# BCM2711_GPIO register map
File version: 1
BCM2711 GPIO controller: pin functions, pulls, levels and event detection
Registers are read-write, no defined reset value unless marked. A register's access mark holds for its fields unless they carry their own. Offsets are from the block's base; lines under a group give offsets from that group; [hi:lo] are bit positions; {n}, {i} and the like mark numbered series; 'fields as' and 'values as' point back to an identical list; <NAME> marks a mode.

## Memory map
0x00000000 BCM2711_GPIO size 0xF4

## BCM2711_GPIO
Base 0x00000000
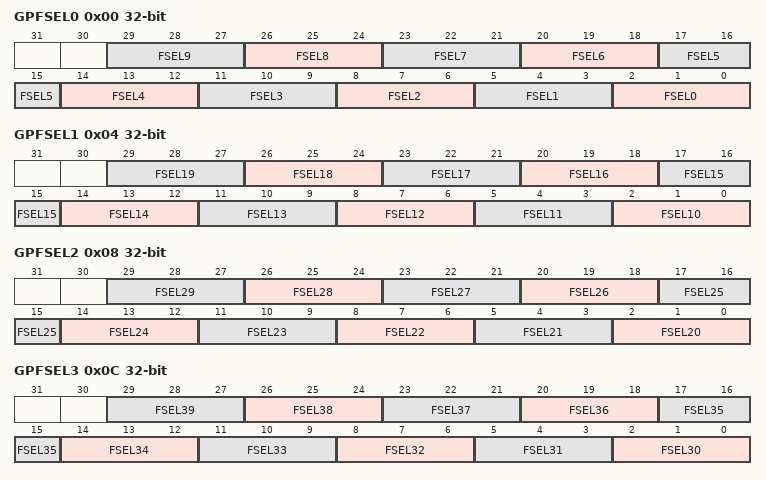
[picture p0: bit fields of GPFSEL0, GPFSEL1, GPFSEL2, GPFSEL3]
0x00 GPFSEL0 — Function select 0 (Table 64): GPIO 0 to 9, each an input, an output or one of its six alternate functions
  [3n+2:3n] FSEL{n} (n=0..9) — FSELn is GPIO n's function
    0=INPUT; 1=OUTPUT; {v}=ALT{v-4} (v=4..7); 3=ALT4; 2=ALT5
0x04 GPFSEL1 — Function select 1 (Table 65): GPIO 10 to 19, each an input, an output or one of its six alternate functions
  [3n-28:3n-30] FSEL{n} (n=10..19) — FSELn is GPIO n's function
    0=INPUT; 1=OUTPUT; {v}=ALT{v-4} (v=4..7); 3=ALT4; 2=ALT5
0x08 GPFSEL2 — Function select 2 (Table 66): GPIO 20 to 29, each an input, an output or one of its six alternate functions
  [3n-58:3n-60] FSEL{n} (n=20..29) — FSELn is GPIO n's function
    0=INPUT; 1=OUTPUT; {v}=ALT{v-4} (v=4..7); 3=ALT4; 2=ALT5
0x0C GPFSEL3 — Function select 3 (Table 67): GPIO 30 to 39, each an input, an output or one of its six alternate functions
  [3n-88:3n-90] FSEL{n} (n=30..39) — FSELn is GPIO n's function
    0=INPUT; 1=OUTPUT; {v}=ALT{v-4} (v=4..7); 3=ALT4; 2=ALT5
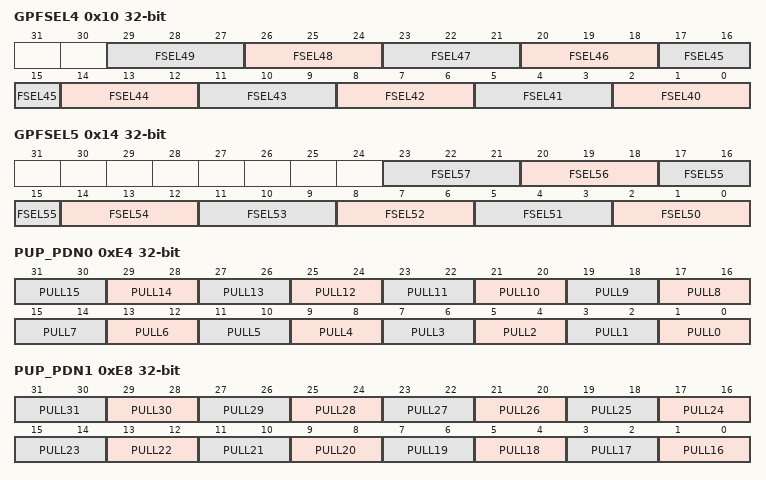
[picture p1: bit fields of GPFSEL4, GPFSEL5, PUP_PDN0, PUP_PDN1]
0x10 GPFSEL4 — Function select 4 (Table 68): GPIO 40 to 49, each an input, an output or one of its six alternate functions
  [3n-118:3n-120] FSEL{n} (n=40..49) — FSELn is GPIO n's function
    0=INPUT; 1=OUTPUT; {v}=ALT{v-4} (v=4..7); 3=ALT4; 2=ALT5
0x14 GPFSEL5 — Function select 5 (Table 69): GPIO 50 to 57, each an input, an output or one of its six alternate functions
  [3n-148:3n-150] FSEL{n} (n=50..57) — FSELn is GPIO n's function
    0=INPUT; 1=OUTPUT; {v}=ALT{v-4} (v=4..7); 3=ALT4; 2=ALT5
0x1C GPSET0 wo — Output set: 1 sets the pin's output, 0 has no effect (Table 70), one bit per GPIO 0 to 31
  [31:0] SET — Bit n is GPIO 0 + n
0x20 GPSET1 wo — Output set: 1 sets the pin's output, 0 has no effect (Table 71), one bit per GPIO 32 to 57
  [25:0] SET — Bit n is GPIO 32 + n
0x28 GPCLR0 wo — Output clear: 1 clears the pin's output, 0 has no effect (Table 72), one bit per GPIO 0 to 31
  [31:0] CLR — Bit n is GPIO 0 + n
0x2C GPCLR1 wo — Output clear: 1 clears the pin's output, 0 has no effect (Table 73), one bit per GPIO 32 to 57
  [25:0] CLR — Bit n is GPIO 32 + n
0x34 GPLEV0 ro — Pin level: 1 the pin is high (Table 74), one bit per GPIO 0 to 31
  [31:0] LEV — Bit n is GPIO 0 + n
0x38 GPLEV1 ro — Pin level: 1 the pin is high (Table 75), one bit per GPIO 32 to 57
  [25:0] LEV — Bit n is GPIO 32 + n
0x40 GPEDS0 — Event detect status: 1 once an enabled edge or level is seen on the pin; writing 1 clears it, and a level still present sets it again (Table 76), one bit per GPIO 0 to 31
  [31:0] EDS write-1-clears — Bit n is GPIO 0 + n
0x44 GPEDS1 — Event detect status: 1 once an enabled edge or level is seen on the pin; writing 1 clears it, and a level still present sets it again (Table 77), one bit per GPIO 32 to 57
  [25:0] EDS write-1-clears — Bit n is GPIO 32 + n
0x4C GPREN0 — Rising edge detect enable, sampled by the system clock (Table 78), one bit per GPIO 0 to 31
  [31:0] REN — Bit n is GPIO 0 + n
0x50 GPREN1 — Rising edge detect enable, sampled by the system clock (Table 79), one bit per GPIO 32 to 57
  [25:0] REN — Bit n is GPIO 32 + n
0x58 GPFEN0 — Falling edge detect enable, sampled by the system clock (Table 80), one bit per GPIO 0 to 31
  [31:0] FEN — Bit n is GPIO 0 + n
0x5C GPFEN1 — Falling edge detect enable, sampled by the system clock (Table 81), one bit per GPIO 32 to 57
  [25:0] FEN — Bit n is GPIO 32 + n
0x64 GPHEN0 — High level detect enable (Table 82), one bit per GPIO 0 to 31
  [31:0] HEN — Bit n is GPIO 0 + n
0x68 GPHEN1 — High level detect enable (Table 83), one bit per GPIO 32 to 57
  [25:0] HEN — Bit n is GPIO 32 + n
0x70 GPLEN0 — Low level detect enable (Table 84), one bit per GPIO 0 to 31
  [31:0] LEN — Bit n is GPIO 0 + n
0x74 GPLEN1 — Low level detect enable (Table 85), one bit per GPIO 32 to 57
  [25:0] LEN — Bit n is GPIO 32 + n
0x7C GPAREN0 — Asynchronous rising edge detect enable (Table 86), one bit per GPIO 0 to 31
  [31:0] AREN — Bit n is GPIO 0 + n
0x80 GPAREN1 — Asynchronous rising edge detect enable (Table 87), one bit per GPIO 32 to 57
  [25:0] AREN — Bit n is GPIO 32 + n
0x88 GPAFEN0 — Asynchronous falling edge detect enable (Table 88), one bit per GPIO 0 to 31
  [31:0] AFEN — Bit n is GPIO 0 + n
0x8C GPAFEN1 — Asynchronous falling edge detect enable (Table 89), one bit per GPIO 32 to 57
  [25:0] AFEN — Bit n is GPIO 32 + n
0xE4 PUP_PDN0 — GPIO_PUP_PDN_CNTRL_REG0 (Table 90): the pull resistor of GPIO 0 to 15; a read gives the current pull; 3 is reserved
  [2n+1:2n] PULL{n} (n=0..15) — PULLn is GPIO n's resistor
    0=NONE; 1=UP; 2=DOWN
0xE8 PUP_PDN1 — GPIO_PUP_PDN_CNTRL_REG1 (Table 91): the pull resistor of GPIO 16 to 31; a read gives the current pull; 3 is reserved
  [2n-31:2n-32] PULL{n} (n=16..31) — PULLn is GPIO n's resistor
    0=NONE; 1=UP; 2=DOWN
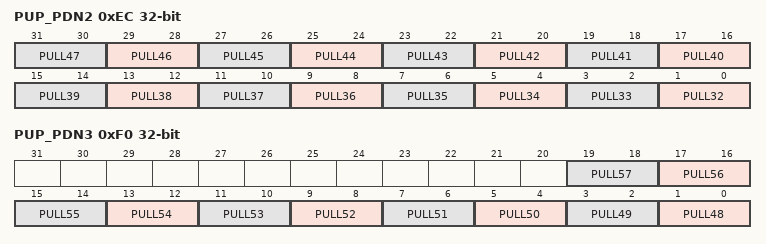
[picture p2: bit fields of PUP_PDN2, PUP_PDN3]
0xEC PUP_PDN2 — GPIO_PUP_PDN_CNTRL_REG2 (Table 92): the pull resistor of GPIO 32 to 47; a read gives the current pull; 3 is reserved
  [2n-63:2n-64] PULL{n} (n=32..47) — PULLn is GPIO n's resistor
    0=NONE; 1=UP; 2=DOWN
0xF0 PUP_PDN3 — GPIO_PUP_PDN_CNTRL_REG3 (Table 93): the pull resistor of GPIO 48 to 57; a read gives the current pull; 3 is reserved
  [2n-95:2n-96] PULL{n} (n=48..57) — PULLn is GPIO n's resistor
    0=NONE; 1=UP; 2=DOWN

## Notices in the file
Copyright (c) 2026, Stanislav Sedov <stas@deglitch.com>
SPDX-License-Identifier: BSD-2-Clause
